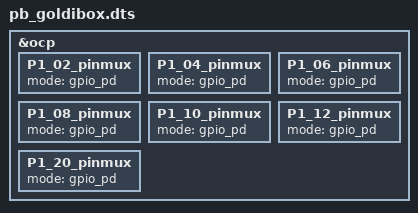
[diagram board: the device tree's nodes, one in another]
/*
 * Goldibox PocketBeagle overlay:  configure output pins

 * sudo dtc -O dtb -o /lib/firmware/pb_goldibox-00A0.dtbo -b 0 -@ pb_goldibox.dts
 * echo dtb_overlay=/lib/firmware/pb_goldibox-00A0.dtbo | sudo tee -a /boot/uEnv.txt

 */

/dts-v1/;
/plugin/;

/{  
    fragment@0 {
	target = <&ocp>;
	__overlay__ {
	    P1_02_pinmux {
		mode = "gpio_pd";
	    };
	    P1_04_pinmux {
		mode = "gpio_pd";
	    };
	    P1_06_pinmux {
		mode = "gpio_pd";
	    };
	    P1_08_pinmux {
		mode = "gpio_pd";
	    };
	    P1_10_pinmux {
		mode = "gpio_pd";
	    };
	    P1_12_pinmux {
		mode = "gpio_pd";
	    };
	    P1_20_pinmux {
		mode = "gpio_pd";
	    };
	};
    };
};
